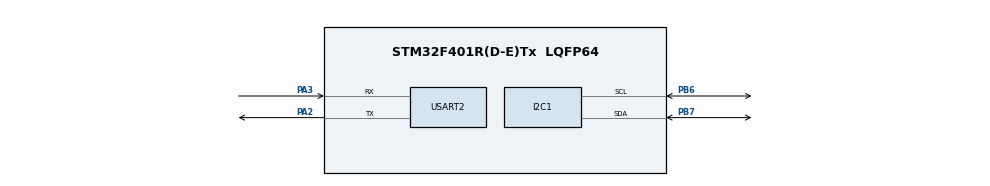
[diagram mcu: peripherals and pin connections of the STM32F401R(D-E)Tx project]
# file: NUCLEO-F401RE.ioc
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Dma.I2C1_RX.0.Direction=DMA_PERIPH_TO_MEMORY
Dma.I2C1_RX.0.FIFOMode=DMA_FIFOMODE_DISABLE
Dma.I2C1_RX.0.Instance=DMA1_Stream0
Dma.I2C1_RX.0.MemDataAlignment=DMA_MDATAALIGN_BYTE
Dma.I2C1_RX.0.MemInc=DMA_MINC_ENABLE
Dma.I2C1_RX.0.Mode=DMA_NORMAL
Dma.I2C1_RX.0.PeriphDataAlignment=DMA_PDATAALIGN_BYTE
Dma.I2C1_RX.0.PeriphInc=DMA_PINC_DISABLE
Dma.I2C1_RX.0.Priority=DMA_PRIORITY_LOW
Dma.I2C1_TX.1.Direction=DMA_MEMORY_TO_PERIPH
Dma.I2C1_TX.1.FIFOMode=DMA_FIFOMODE_DISABLE
Dma.I2C1_TX.1.Instance=DMA1_Stream6
Dma.I2C1_TX.1.MemDataAlignment=DMA_MDATAALIGN_BYTE
Dma.I2C1_TX.1.MemInc=DMA_MINC_ENABLE
Dma.I2C1_TX.1.Mode=DMA_NORMAL
Dma.I2C1_TX.1.PeriphDataAlignment=DMA_PDATAALIGN_BYTE
Dma.I2C1_TX.1.PeriphInc=DMA_PINC_DISABLE
Dma.I2C1_TX.1.Priority=DMA_PRIORITY_LOW
Dma.Request0=I2C1_RX
Dma.Request1=I2C1_TX
Mcu.Family=STM32F4
Mcu.Name=STM32F401R(D-E)Tx
Mcu.Package=LQFP64
NVIC.DMA1_Stream0_IRQn=true\:0\:0\:false\:false\:true\:false\:true\:true
NVIC.DMA1_Stream6_IRQn=true\:0\:0\:false\:false\:true\:false\:true\:true
NVIC.PriorityGroup=NVIC_PRIORITYGROUP_4
PA13.Mode=Serial_Wire
PA13.Signal=SYS_JTMS-SWDIO
PA14.Mode=Serial_Wire
PA14.Signal=SYS_JTCK-SWCLK
PA2.Mode=Asynchronous
PA2.Signal=USART2_TX
PA3.Mode=Asynchronous
PA3.Signal=USART2_RX
PB6.Mode=I2C
PB6.Signal=I2C1_SCL
PB7.Mode=I2C
PB7.Signal=I2C1_SDA
ProjectManager.HeapSize=0x200
ProjectManager.StackSize=0x400
ProjectManager.TargetToolchain=STM32CubeIDE
RCC.48MHZClocksFreq_Value=48000000
RCC.AHBFreq_Value=84000000
RCC.APB1CLKDivider=RCC_HCLK_DIV2
RCC.APB1Freq_Value=42000000
RCC.APB1TimFreq_Value=84000000
RCC.APB2Freq_Value=84000000
RCC.APB2TimFreq_Value=84000000
RCC.CortexFreq_Value=84000000
RCC.HCLKFreq_Value=84000000
RCC.HSE_VALUE=8000000
RCC.HSI_VALUE=16000000
RCC.LSE_VALUE=32768
RCC.PLLN=336
RCC.PLLP=RCC_PLLP_DIV4
RCC.PLLQ=7
RCC.SYSCLKFreq_VALUE=84000000
RCC.SYSCLKSource=RCC_SYSCLKSOURCE_PLLCLK
RCC.VCOOutputFreq_Value=336000000
USART2.Parity=PARITY_EVEN
USART2.VirtualMode=VM_ASYNC
USART2.WordLength=WORDLENGTH_9B
board=NUCLEO-F401RE

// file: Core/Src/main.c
/* USER CODE BEGIN Header */
/**
 ******************************************************************************
 * @file           : main.c
 * @brief          : Main program body
 ******************************************************************************
 * @attention
 *
 * Copyright (c) 2026 STMicroelectronics.
 * All rights reserved.
 *
 * This software is licensed under terms that can be found in the LICENSE file
 * in the root directory of this software component.
 * If no LICENSE file comes with this software, it is provided AS-IS.
 *
 ******************************************************************************
 */
/* USER CODE END Header */
#include "main.h"
#include "dma.h"
#include "i2c.h"
#include "usart.h"
#include "gpio.h"

/* USER CODE BEGIN Includes */
#include "main_app.h"
/* USER CODE END Includes */

void SystemClock_Config(void);

int main(void)
{

  /* MCU Configuration--------------------------------------------------------*/

  /* Reset of all peripherals, Initializes the Flash interface and the Systick. */
  LL_APB2_GRP1_EnableClock(LL_APB2_GRP1_PERIPH_SYSCFG);
  LL_APB1_GRP1_EnableClock(LL_APB1_GRP1_PERIPH_PWR);

  /* System interrupt init*/
  NVIC_SetPriorityGrouping(NVIC_PRIORITYGROUP_4);

  /* Configure the system clock */
  SystemClock_Config();

  /* Initialize all configured peripherals */
  MX_GPIO_Init();
  MX_DMA_Init();
  MX_I2C1_Init();
  MX_USART2_UART_Init();
  /* USER CODE BEGIN 2 */
  app_main(); // Call the main application function
  /* USER CODE END 2 */

  /* Infinite loop */
  while (1)
  {

  }
}

void SystemClock_Config(void)
{
  LL_FLASH_SetLatency(LL_FLASH_LATENCY_2);
  while(LL_FLASH_GetLatency()!= LL_FLASH_LATENCY_2)
  {
  }
  LL_PWR_SetRegulVoltageScaling(LL_PWR_REGU_VOLTAGE_SCALE2);
  LL_RCC_HSI_SetCalibTrimming(16);
  LL_RCC_HSI_Enable();

   /* Wait till HSI is ready */
  while(LL_RCC_HSI_IsReady() != 1)
  {

  }
  LL_RCC_PLL_ConfigDomain_SYS(LL_RCC_PLLSOURCE_HSI, LL_RCC_PLLM_DIV_16, 336, LL_RCC_PLLP_DIV_4);
  LL_RCC_PLL_Enable();

   /* Wait till PLL is ready */
  while(LL_RCC_PLL_IsReady() != 1)
  {

  }
  while (LL_PWR_IsActiveFlag_VOS() == 0)
  {
  }
  LL_RCC_SetAHBPrescaler(LL_RCC_SYSCLK_DIV_1);
  LL_RCC_SetAPB1Prescaler(LL_RCC_APB1_DIV_2);
  LL_RCC_SetAPB2Prescaler(LL_RCC_APB2_DIV_1);
  LL_RCC_SetSysClkSource(LL_RCC_SYS_CLKSOURCE_PLL);

   /* Wait till System clock is ready */
  while(LL_RCC_GetSysClkSource() != LL_RCC_SYS_CLKSOURCE_STATUS_PLL)
  {

  }
  LL_Init1msTick(84000000);
  LL_SetSystemCoreClock(84000000);
  LL_RCC_SetTIMPrescaler(LL_RCC_TIM_PRESCALER_TWICE);
}

void Error_Handler(void)
{
  __disable_irq();
  while (1)
  {
  }
}
